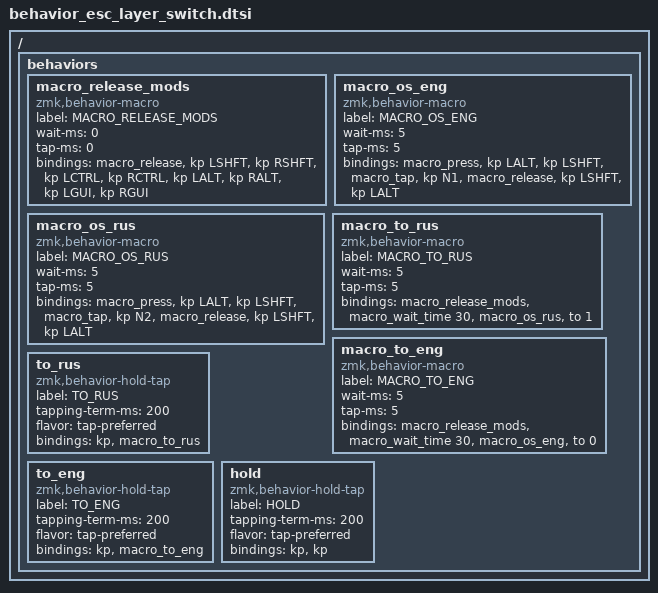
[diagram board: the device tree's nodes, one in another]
/ {
  behaviors {
    macro_release_mods: macro_release_mods {
      compatible = "zmk,behavior-macro";
      label = "MACRO_RELEASE_MODS";
      #binding-cells = <0>;
      wait-ms = <0>;
      tap-ms = <0>;
      bindings = <&macro_release &kp LSHFT &kp RSHFT &kp LCTRL &kp RCTRL &kp LALT &kp RALT &kp LGUI &kp RGUI>;
    };

    macro_os_eng: macro_os_eng {
      compatible = "zmk,behavior-macro";
      label = "MACRO_OS_ENG";
      #binding-cells = <0>;
      wait-ms = <5>;
      tap-ms = <5>;
      bindings = <&macro_press &kp LALT &kp LSHFT>
               , <&macro_tap &kp N1>
               , <&macro_release &kp LSHFT &kp LALT>;
    };

    macro_os_rus: macro_os_rus {
      compatible = "zmk,behavior-macro";
      label = "MACRO_OS_RUS";
      #binding-cells = <0>;
      wait-ms = <5>;
      tap-ms = <5>;
      bindings = <&macro_press &kp LALT &kp LSHFT>
               , <&macro_tap &kp N2>
               , <&macro_release &kp LSHFT &kp LALT>;
    };

    macro_to_rus: macro_to_rus {
      compatible = "zmk,behavior-macro";
      label = "MACRO_TO_RUS";
      #binding-cells = <0>;
      wait-ms = <5>;
      tap-ms = <5>;
      bindings = <&macro_release_mods>
               , <&macro_wait_time 30>
               , <&macro_os_rus>
               , <&to 1>;
    };

    macro_to_eng: macro_to_eng {
      compatible = "zmk,behavior-macro";
      label = "MACRO_TO_ENG";
      #binding-cells = <0>;
      wait-ms = <5>;
      tap-ms = <5>;
      bindings = <&macro_release_mods>
               , <&macro_wait_time 30>
               , <&macro_os_eng>
               , <&to 0>;
    };

    to_rus: to_rus {
      compatible = "zmk,behavior-hold-tap";
      label = "TO_RUS";
      #binding-cells = <2>;
      tapping-term-ms = <200>;
      flavor = "tap-preferred";
      bindings = <&kp>, <&macro_to_rus>;
    };

    to_eng: to_eng {
      compatible = "zmk,behavior-hold-tap";
      label = "TO_ENG";
      #binding-cells = <2>;
      tapping-term-ms = <200>;
      flavor = "tap-preferred";
      bindings = <&kp>, <&macro_to_eng>;
    };

    hold: hold {
      compatible = "zmk,behavior-hold-tap";
      label = "HOLD";
      #binding-cells = <2>;
      tapping-term-ms = <200>;
      flavor = "tap-preferred";
      bindings = <&kp>, <&kp>;
    };
  };
};
